# PIC18LF8723 register map
Vendor: Microchip
Architecture 18xxxx. Special function registers and configuration words.
Registers are 8-bit, read-write, reset 0x0 unless marked. A register's access mark holds for its fields unless they carry their own. Addresses are absolute, and some are shared; only a register's first bit layout is shown; lines under a group give offsets from that group; [hi:lo] are bit positions; {n}, {i} and the like mark numbered series; 'fields as' and 'values as' point back to an identical list; <NAME> marks a mode.

## Further device data
pins=1: RH2/A18; 2: RH3/A19; 3: RE1/AD9/WR/P2C; 4: RE0/AD8/RD/P2D; 5: RG0/ECCP3/P3A; 6: RG1/TX2/CK2; 7: RG2/RX2/DT2; 8: RG3/CCP4/P3D; 9: RG5/MCLR/Vpp; 10: RG4/CCP5/P1D; 11: Vss; 12: Vdd; 13: RF7/SS1; 14: RF6/AN11; 15: RF5/AN10/CVref; 16: RF4/AN9; 17: RF3/AN8; 18: RF2/AN7/C1OUT; 19: RH7/AN15/P1B; 20: RH6/AN14/P1C; 21: RH5/AN13/P3B; 22: RH4/AN12/P3C; 23: RF1/AN6/C2OUT; 24: RF0/AN5; 25: AVdd; 26: AVss; 27: RA3/AN3/Vref+; 28: RA2/AN2/Vref-; 29: RA1/AN1; 30: RA0/AN0; 31: Vss; 32: Vdd; 33: RA5/AN4/HLVDIN; 34: RA4/T0CKI; 35: RC1/T1OSI/ECCP2/P2A; 36: RC0/T1OSO/T13CKI; 37: RC6/TX1/CK1; 38: RC7/RX1/DT1; 39: RJ4/BA0; 40: RJ5/CE; 41: RJ6/LB; 42: RJ7/UB; 43: RC2/ECCP1/P1A; 44: RC3/SCK1/SCL1; 45: RC4/SDI1/SDA1; 46: RC5/SDO1; 47: RB7/KBI3/PGD; 48: Vdd; 49: OSC1/CLKI/RA7; 50: OSC2/CLKO/RA6; 51: Vss; 52: RB6/KBI2/PGC; 53: RB5/KBI1/PGM; 54: RB4/KBI0; 55: RB3/INT3/ECCP2/P2A; 56: RB2/INT2; 57: RB1/INT1; 58: RB0/INT0/FLT0; 59: RJ3/WRH; 60: RJ2/WRL; 61: RJ1/OE; 62: RJ0/ALE; 63: RD7/AD7/PSP7/SS2; 64: RD6/AD6/PSP6/SCK2/SCL2; 65: RD5/AD5/PSP5/SDI2/SDA2; 66: RD4/AD4/PSP4/SDO2; 67: RD3/AD3/PSP3; 68: RD2/AD2/PSP2; 69: RD1/AD1/PSP1; 70: Vss; 71: Vdd; 72: RD0/AD0/PSP0; 73: RE7/AD15/ECCP2/P2A; 74: RE6/AD14/P1B; 75: RE5/AD13/P1C; 76: RE4/AD12/P3B; 77: RE3/AD11/P3C; 78: RE2/AD10/CS/P2B; 79: RH0/A16; 80: RH1/A17

## SFR
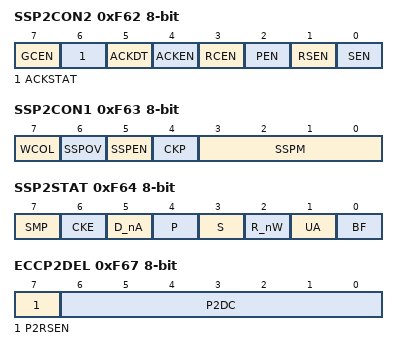
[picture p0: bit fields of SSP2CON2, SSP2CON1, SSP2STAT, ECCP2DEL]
0xF62 SSP2CON2
  [7] GCEN, [6] ACKSTAT, [5] ACKDT, [4] ACKEN, [3] RCEN, [2] PEN, [1] RSEN, [0] SEN
0xF63 SSP2CON1
  [7] WCOL, [6] SSPOV, [5] SSPEN, [4] CKP, [3:0] SSPM
0xF64 SSP2STAT
  [7] SMP, [6] CKE, [5] D_nA, [4] P, [3] S, [2] R_nW, [1] UA, [0] BF
0xF65 SSP2ADD
  [7:0] SSPADD
0xF66 SSP2BUF reset not defined — (power-on value xxxxxxxx)
  [7:0] SSPBUF
0xF67 ECCP2DEL
  [7] P2RSEN, [6:0] P2DC
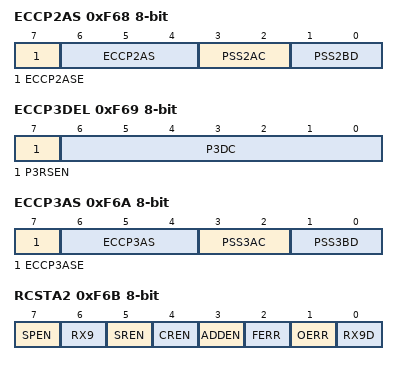
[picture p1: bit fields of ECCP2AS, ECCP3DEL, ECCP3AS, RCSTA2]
0xF68 ECCP2AS
  [7] ECCP2ASE, [6:4] ECCP2AS, [3:2] PSS2AC, [1:0] PSS2BD
0xF69 ECCP3DEL
  [7] P3RSEN, [6:0] P3DC
0xF6A ECCP3AS
  [7] ECCP3ASE, [6:4] ECCP3AS, [3:2] PSS3AC, [1:0] PSS3BD
0xF6B RCSTA2 reset not defined — (power-on value 0000000x)
  [7] SPEN, [6] RX9, [5] SREN, [4] CREN, [3] ADDEN, [2] FERR ro, [1] OERR ro, [0] RX9D ro
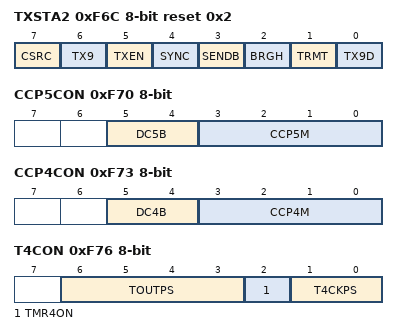
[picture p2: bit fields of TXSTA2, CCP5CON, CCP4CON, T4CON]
0xF6C TXSTA2 reset 0x2
  [7] CSRC, [6] TX9, [5] TXEN, [4] SYNC, [3] SENDB, [2] BRGH, [1] TRMT ro, [0] TX9D
0xF6D TXREG2 wo
  [7:0] TXREG
0xF6E RCREG2 ro
  [7:0] RCREG
0xF6F SPBRG2
  [7:0] SPBRG
0xF70 CCP5CON
  [5:4] DC5B, [3:0] CCP5M
0xF71 CCPR5L reset not defined — (power-on value xxxxxxxx)
0xF72 CCPR5H reset not defined — (power-on value xxxxxxxx)
0xF73 CCP4CON
  [5:4] DC4B, [3:0] CCP4M
0xF74 CCPR4L reset not defined — (power-on value xxxxxxxx)
0xF75 CCPR4H reset not defined — (power-on value xxxxxxxx)
0xF76 T4CON
  [6:3] TOUTPS, [2] TMR4ON, [1:0] T4CKPS
0xF77 PR4 reset 0xFF
0xF78 TMR4
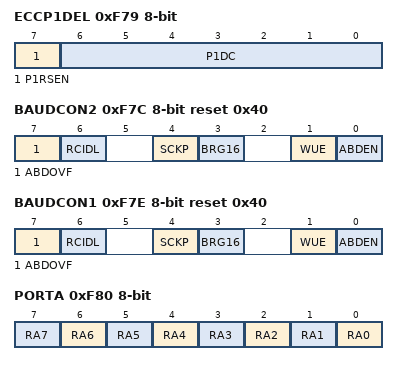
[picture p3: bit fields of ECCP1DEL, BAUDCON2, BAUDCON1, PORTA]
0xF79 ECCP1DEL
  [7] P1RSEN, [6:0] P1DC
0xF7C BAUDCON2 reset 0x40
  [7] ABDOVF — (can only be cleared)
  [6] RCIDL ro
  [4] SCKP
  [3] BRG16
  [1] WUE
  [0] ABDEN
0xF7D SPBRGH2
0xF7E BAUDCON1 reset 0x40
  fields as BAUDCON2
0xF7F SPBRGH1
0xF80 PORTA reset not defined — (power-on value xx0x0000)
  [n] RA{n} (n=0..7)
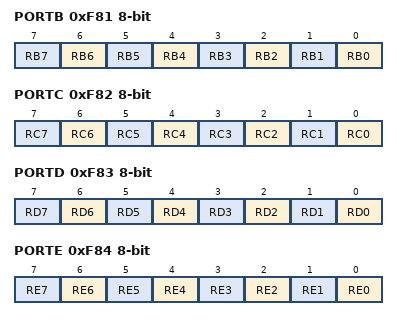
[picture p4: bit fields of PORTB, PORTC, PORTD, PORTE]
0xF81 PORTB reset not defined — (power-on value xxxxxxxx)
  [n] RB{n} (n=0..7)
0xF82 PORTC reset not defined — (power-on value xxxxxxxx)
  [n] RC{n} (n=0..7)
0xF83 PORTD reset not defined — (power-on value xxxxxxxx)
  [n] RD{n} (n=0..7)
0xF84 PORTE reset not defined — (power-on value xxxxxxxx)
  [n] RE{n} (n=0..7)
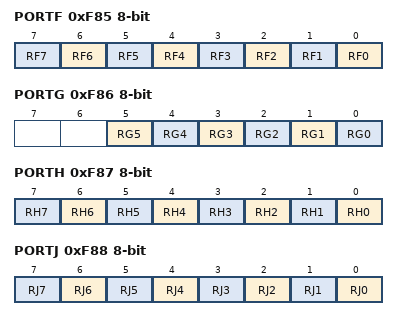
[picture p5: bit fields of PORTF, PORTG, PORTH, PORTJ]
0xF85 PORTF reset not defined — (power-on value xxxxxxxx)
  [n] RF{n} (n=0..7)
0xF86 PORTG reset not defined — (power-on value --xxxxxx)
  [5] RG5 ro, [n] RG{n} (n=0..4)
0xF87 PORTH reset not defined — (power-on value xxxxxxxx)
  [n] RH{n} (n=0..7)
0xF88 PORTJ reset not defined — (power-on value xxxxxxxx)
  [n] RJ{n} (n=0..7)
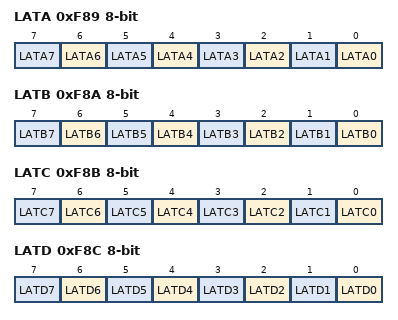
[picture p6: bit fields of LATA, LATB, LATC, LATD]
0xF89 LATA reset not defined — (power-on value xxxxxxxx)
  [n] LATA{n} (n=0..7)
0xF8A LATB reset not defined — (power-on value xxxxxxxx)
  [n] LATB{n} (n=0..7)
0xF8B LATC reset not defined — (power-on value xxxxxxxx)
  [n] LATC{n} (n=0..7)
0xF8C LATD reset not defined — (power-on value xxxxxxxx)
  [n] LATD{n} (n=0..7)
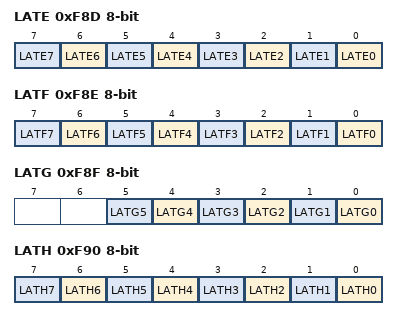
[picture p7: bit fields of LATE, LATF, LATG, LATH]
0xF8D LATE reset not defined — (power-on value xxxxxxxx)
  [n] LATE{n} (n=0..7)
0xF8E LATF reset not defined — (power-on value xxxxxxxx)
  [n] LATF{n} (n=0..7)
0xF8F LATG reset not defined — (power-on value ---xxxxx)
  [n] LATG{n} (n=0..5)
0xF90 LATH reset not defined — (power-on value xxxxxxxx)
  [n] LATH{n} (n=0..7)
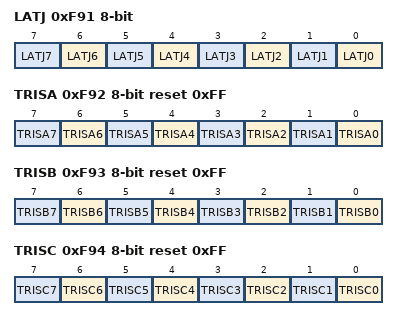
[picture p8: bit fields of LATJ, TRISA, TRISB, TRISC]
0xF91 LATJ reset not defined — (power-on value xxxxxxxx)
  [n] LATJ{n} (n=0..7)
0xF92 TRISA reset 0xFF
  [n] TRISA{n} (n=0..7)
0xF93 TRISB reset 0xFF
  [n] TRISB{n} (n=0..7)
0xF94 TRISC reset 0xFF
  [n] TRISC{n} (n=0..7)
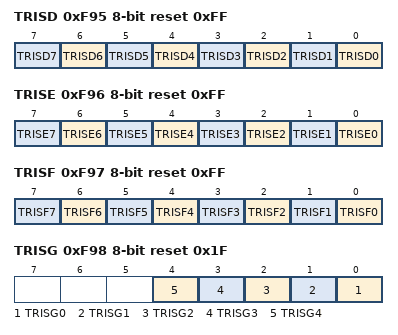
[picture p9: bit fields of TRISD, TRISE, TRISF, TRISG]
0xF95 TRISD reset 0xFF
  [n] TRISD{n} (n=0..7)
0xF96 TRISE reset 0xFF
  [n] TRISE{n} (n=0..7)
0xF97 TRISF reset 0xFF
  [n] TRISF{n} (n=0..7)
0xF98 TRISG reset 0x1F
  [n] TRISG{n} (n=0..4)
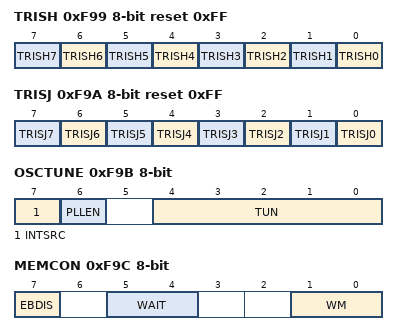
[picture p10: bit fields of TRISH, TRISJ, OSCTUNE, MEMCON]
0xF99 TRISH reset 0xFF
  [n] TRISH{n} (n=0..7)
0xF9A TRISJ reset 0xFF
  [n] TRISJ{n} (n=0..7)
0xF9B OSCTUNE
  [7] INTSRC, [6] PLLEN, [4:0] TUN
0xF9C MEMCON
  [7] EBDIS, [5:4] WAIT, [1:0] WM
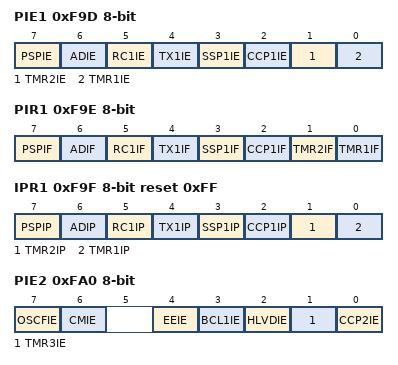
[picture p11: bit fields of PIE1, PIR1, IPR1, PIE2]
0xF9D PIE1
  [7] PSPIE, [6] ADIE, [5] RC1IE, [4] TX1IE, [3] SSP1IE, [2] CCP1IE, [1] TMR2IE, [0] TMR1IE
0xF9E PIR1
  [7] PSPIF, [6] ADIF, [5] RC1IF ro, [4] TX1IF ro, [3] SSP1IF, [2] CCP1IF, [1] TMR2IF, [0] TMR1IF
0xF9F IPR1 reset 0xFF
  [7] PSPIP, [6] ADIP, [5] RC1IP, [4] TX1IP, [3] SSP1IP, [2] CCP1IP, [1] TMR2IP, [0] TMR1IP
0xFA0 PIE2
  [7] OSCFIE, [6] CMIE, [4] EEIE, [3] BCL1IE, [2] HLVDIE, [1] TMR3IE, [0] CCP2IE
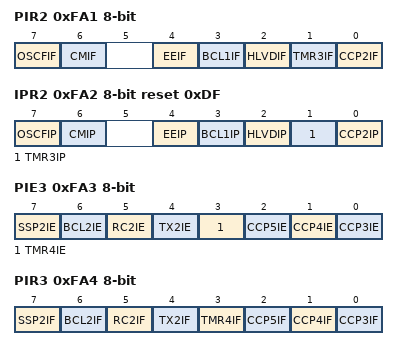
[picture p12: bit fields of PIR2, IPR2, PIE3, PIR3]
0xFA1 PIR2
  [7] OSCFIF, [6] CMIF, [4] EEIF, [3] BCL1IF, [2] HLVDIF, [1] TMR3IF, [0] CCP2IF
0xFA2 IPR2 reset 0xDF
  [7] OSCFIP, [6] CMIP, [4] EEIP, [3] BCL1IP, [2] HLVDIP, [1] TMR3IP, [0] CCP2IP
0xFA3 PIE3
  [7] SSP2IE, [6] BCL2IE, [5] RC2IE, [4] TX2IE, [3] TMR4IE, [2] CCP5IE, [1] CCP4IE, [0] CCP3IE
0xFA4 PIR3
  [7] SSP2IF, [6] BCL2IF, [5] RC2IF ro, [4] TX2IF ro, [3] TMR4IF, [2] CCP5IF, [1] CCP4IF, [0] CCP3IF
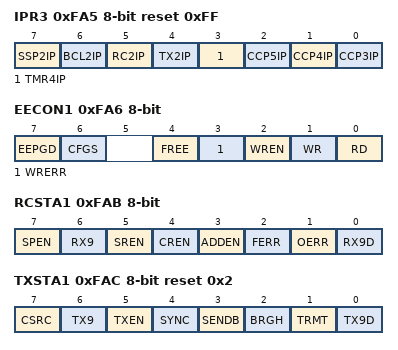
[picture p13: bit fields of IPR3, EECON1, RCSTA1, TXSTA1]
0xFA5 IPR3 reset 0xFF
  [7] SSP2IP, [6] BCL2IP, [5] RC2IP, [4] TX2IP, [3] TMR4IP, [2] CCP5IP, [1] CCP4IP, [0] CCP3IP
0xFA6 EECON1 reset not defined — (power-on value xx-0x000)
  [7] EEPGD
  [6] CFGS
  [4] FREE
  [3] WRERR
  [2] WREN
  [1] WR — (can only be set)
  [0] RD — (can only be set)
0xFA7 EECON2 wo reset not defined
0xFA8 EEDATA
0xFA9 EEADR
0xFAA EEADRH
  [1:0] EEADRH
0xFAB RCSTA1 reset not defined — (power-on value 0000000x)
  fields as RCSTA2
0xFAC TXSTA1 reset 0x2
  fields as TXSTA2
0xFAD TXREG1 wo
  [7:0] TXREG
0xFAE RCREG1 ro
  [7:0] RCREG
0xFAF SPBRG1
  [7:0] SPBRG
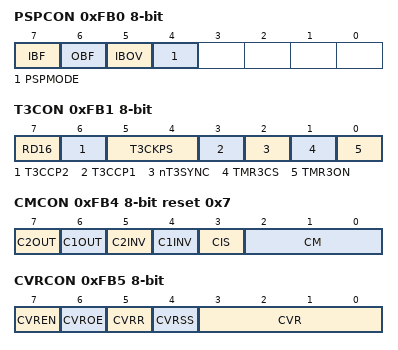
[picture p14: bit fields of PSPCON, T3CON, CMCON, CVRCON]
0xFB0 PSPCON
  [7] IBF, [6] OBF, [5] IBOV, [4] PSPMODE
0xFB1 T3CON
  [7] RD16, [6] T3CCP2, [5:4] T3CKPS, [3] T3CCP1, [2] nT3SYNC, [1] TMR3CS, [0] TMR3ON
0xFB2 TMR3L reset not defined — (power-on value xxxxxxxx)
0xFB3 TMR3H reset not defined — (power-on value xxxxxxxx)
0xFB4 CMCON reset 0x7
  [7] C2OUT ro, [6] C1OUT ro, [5] C2INV, [4] C1INV, [3] CIS, [2:0] CM
0xFB5 CVRCON
  [7] CVREN, [6] CVROE, [5] CVRR, [4] CVRSS, [3:0] CVR
0xFB6 ECCP1AS
  [7] ECCP1ASE, [6:4] ECCP1AS, [3:2] PSS1AC, [1:0] PSS1BD
0xFB7 CCP3CON
  [7:6] P3M, [5:4] DC3B, [3:0] CCP3M
0xFB8 CCPR3L reset not defined — (power-on value xxxxxxxx)
0xFB9 CCPR3H reset not defined — (power-on value xxxxxxxx)
0xFBA CCP2CON
  [7:6] P2M, [5:4] DC2B, [3:0] CCP2M
0xFBB CCPR2L reset not defined — (power-on value xxxxxxxx)
0xFBC CCPR2H reset not defined — (power-on value xxxxxxxx)
0xFBD CCP1CON
  [7:6] P1M, [5:4] DC1B, [3:0] CCP1M
0xFBE CCPR1L reset not defined — (power-on value xxxxxxxx)
0xFBF CCPR1H reset not defined — (power-on value xxxxxxxx)
0xFC0 ADCON2
  [7] ADFM, [5:3] ACQT, [2:0] ADCS
0xFC1 ADCON1 reset not defined — (power-on value --00qqqq)
  [5:4] VCFG, [3:0] PCFG
0xFC2 ADCON0
  [5:2] CHS, [1] GO_nDONE, [0] ADON
0xFC3 ADRESL reset not defined — (power-on value xxxxxxxx)
0xFC4 ADRESH reset not defined — (power-on value xxxxxxxx)
0xFC5 SSP1CON2
  fields as SSP2CON2
0xFC6 SSP1CON1
  [7] WCOL, [6] SSPOV, [5] SSPEN, [4] CKP, [3:0] SSPM
0xFC7 SSP1STAT
  [7] SMP, [6] CKE, [5] D_nA, [4] P, [3] S, [2] R_nW, [1] UA, [0] BF
0xFC8 SSP1ADD
  [7:0] SSPADD
0xFC9 SSP1BUF reset not defined — (power-on value xxxxxxxx)
  [7:0] SSPBUF
0xFCA T2CON
  [6:3] TOUTPS, [2] TMR2ON, [1:0] T2CKPS
0xFCB PR2 reset 0xFF
0xFCC TMR2
0xFCD T1CON
  [7] RD16, [6] T1RUN ro, [5:4] T1CKPS, [3] T1OSCEN, [2] nT1SYNC, [1] TMR1CS, [0] TMR1ON
0xFCE TMR1L reset not defined — (power-on value xxxxxxxx)
0xFCF TMR1H reset not defined — (power-on value xxxxxxxx)
0xFD0 RCON reset 0x5C
  [7] IPEN, [6] SBOREN, [4] nRI, [3] nTO, [2] nPD, [1] nPOR, [0] nBOR
0xFD1 WDTCON
  [0] SWDTEN
0xFD2 HLVDCON reset 0x5
  [7] VDIRMAG, [5] IRVST, [4] HLVDEN, [3:0] HLVDL
0xFD3 OSCCON reset 0x40
  [7] IDLEN, [6:4] IRCF, [3] OSTS, [2] IOFS ro, [1:0] SCS
0xFD5 T0CON reset 0xFF
  [7] TMR0ON, [6] T08BIT, [5] T0CS, [4] T0SE, [3] PSA, [2:0] T0PS
0xFD6 TMR0L reset not defined — (power-on value xxxxxxxx)
0xFD7 TMR0H
0xFD8 STATUS reset not defined — (power-on value ---xxxxx)
  [4] N, [3] OV, [2] Z, [1] DC, [0] C
0xFD9 FSR2L reset not defined — (power-on value xxxxxxxx)
0xFDA FSR2H
  [3:0] FSR2H
0xFDB PLUSW2 access not given reset not defined
0xFDC PREINC2 access not given reset not defined
0xFDD POSTDEC2 access not given reset not defined
0xFDE POSTINC2 access not given reset not defined
0xFDF INDF2 access not given reset not defined
0xFE0 BSR
  [3:0] BSR
0xFE1 FSR1L reset not defined — (power-on value xxxxxxxx)
0xFE2 FSR1H
  [3:0] FSR1H
0xFE3 PLUSW1 access not given reset not defined
0xFE4 PREINC1 access not given reset not defined
0xFE5 POSTDEC1 access not given reset not defined
0xFE6 POSTINC1 access not given reset not defined
0xFE7 INDF1 access not given reset not defined
0xFE8 WREG reset not defined — (power-on value xxxxxxxx)
0xFE9 FSR0L reset not defined — (power-on value xxxxxxxx)
0xFEA FSR0H
  [3:0] FSR0H
0xFEB PLUSW0 access not given reset not defined
0xFEC PREINC0 access not given reset not defined
0xFED POSTDEC0 access not given reset not defined
0xFEE POSTINC0 access not given reset not defined
0xFEF INDF0 access not given reset not defined
0xFF0 INTCON3 reset 0xC0
  [7] INT2IP, [6] INT1IP, [5] INT3IE, [4] INT2IE, [3] INT1IE, [2] INT3IF, [1] INT2IF, [0] INT1IF
0xFF1 INTCON2 reset 0xFF
  [7] nRBPU, [6-n] INTEDG{n} (n=0..3), [2] TMR0IP, [1] INT3IP, [0] RBIP
0xFF2 INTCON reset not defined — (power-on value 0000000x)
  [7] GIE_GIEH, [6] PEIE_GIEL, [5] TMR0IE, [4] INT0IE, [3] RBIE, [2] TMR0IF, [1] INT0IF, [0] RBIF
0xFF3 PRODL reset not defined — (power-on value xxxxxxxx)
0xFF4 PRODH reset not defined — (power-on value xxxxxxxx)
0xFF5 TABLAT
0xFF6 TBLPTRL
0xFF7 TBLPTRH
0xFF8 TBLPTRU
  [5] ACSS, [4:0] TBLPTRU
0xFF9 PCL
0xFFA PCLATH
  [7:0] PCH
0xFFB PCLATU
  [4:0] PCU
0xFFC STKPTR
  [7] STKFUL — (can only be cleared)
  [6] STKUNF — (can only be cleared)
  [4:0] STKPTR
0xFFD TOSL
0xFFE TOSH
0xFFF TOSU
  [4:0] TOSU
